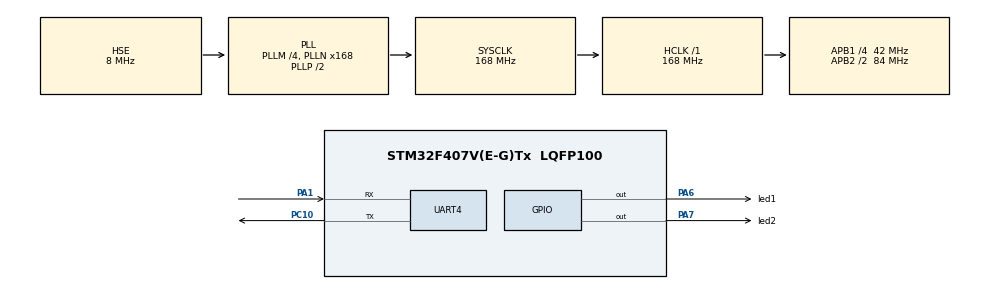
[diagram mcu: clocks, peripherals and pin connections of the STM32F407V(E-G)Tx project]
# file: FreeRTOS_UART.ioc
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FREERTOS.BinarySemaphores01=uartBinarySem,Dynamic,NULL;mainBinarySem,Dynamic,NULL
FREERTOS.Tasks01=defaultTask,0,128,StartDefaultTask,Default,NULL,Dynamic,NULL,NULL;uartProcess,0,128,StartUartProcess,Default,NULL,Dynamic,NULL,NULL
Mcu.Family=STM32F4
Mcu.Name=STM32F407V(E-G)Tx
Mcu.Package=LQFP100
NVIC.PriorityGroup=NVIC_PRIORITYGROUP_4
NVIC.TIM7_IRQn=true\:0\:0\:false\:false\:true\:false\:false\:true
NVIC.TimeBase=TIM7_IRQn
NVIC.TimeBaseIP=TIM7
NVIC.UART4_IRQn=true\:5\:0\:true\:false\:true\:true\:true\:true
PA1.Mode=Asynchronous
PA1.Signal=UART4_RX
PA13.Mode=Serial_Wire
PA13.Signal=SYS_JTMS-SWDIO
PA14.Mode=Serial_Wire
PA14.Signal=SYS_JTCK-SWCLK
PA6.GPIO_Label=led1
PA6.Signal=GPIO_Output
PA7.GPIO_Label=led2
PA7.GPIO_PuPd=GPIO_PULLDOWN
PA7.Signal=GPIO_Output
PC10.Mode=Asynchronous
PC10.Signal=UART4_TX
PH0-OSC_IN.Mode=HSE-External-Oscillator
PH0-OSC_IN.Signal=RCC_OSC_IN
PH1-OSC_OUT.Mode=HSE-External-Oscillator
PH1-OSC_OUT.Signal=RCC_OSC_OUT
ProjectManager.HeapSize=0x200
ProjectManager.StackSize=0x400
ProjectManager.TargetToolchain=STM32CubeIDE
RCC.48MHZClocksFreq_Value=84000000
RCC.AHBFreq_Value=168000000
RCC.APB1CLKDivider=RCC_HCLK_DIV4
RCC.APB1Freq_Value=42000000
RCC.APB1TimFreq_Value=84000000
RCC.APB2CLKDivider=RCC_HCLK_DIV2
RCC.APB2Freq_Value=84000000
RCC.APB2TimFreq_Value=168000000
RCC.CortexFreq_Value=168000000
RCC.HCLKFreq_Value=168000000
RCC.HSE_VALUE=8000000
RCC.HSI_VALUE=16000000
RCC.LSE_VALUE=32768
RCC.PLLM=4
RCC.PLLN=168
RCC.PLLSourceVirtual=RCC_PLLSOURCE_HSE
RCC.SYSCLKFreq_VALUE=168000000
RCC.SYSCLKSource=RCC_SYSCLKSOURCE_PLLCLK
RCC.VCOOutputFreq_Value=336000000
UART4.VirtualMode=Asynchronous
VP_FREERTOS_VS_CMSIS_V1.Mode=CMSIS_V1
VP_SYS_VS_tim7.Mode=TIM7
board=custom

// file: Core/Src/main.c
/* USER CODE BEGIN Header */
/**
  ******************************************************************************
  * @file           : main.c
  * @brief          : Main program body
  ******************************************************************************
  * @attention
  *
  * <h2><center>&copy; Copyright (c) 2020 STMicroelectronics.
  * All rights reserved.</center></h2>
  *
  * This software component is licensed by ST under BSD 3-Clause license,
  * the "License"; You may not use this file except in compliance with the
  * License. You may obtain a copy of the License at:
  *                        opensource.org/licenses/BSD-3-Clause
  *
  ******************************************************************************
  */
/* USER CODE END Header */

#include "main.h"
#include "cmsis_os.h"

/* USER CODE BEGIN Includes */
#include <stdio.h>
/* USER CODE END Includes */

UART_HandleTypeDef huart4;

osThreadId defaultTaskHandle;
osThreadId uartProcessHandle;
osSemaphoreId uartBinarySemHandle;
osSemaphoreId mainBinarySemHandle;
/* USER CODE BEGIN PV */
volatile char recievedData[50];
/* USER CODE END PV */

void SystemClock_Config(void);
static void MX_GPIO_Init(void);
static void MX_UART4_Init(void);
void StartDefaultTask(void const * argument);
void StartUartProcess(void const * argument);

/* USER CODE BEGIN 0 */
void HAL_UART_RxCpltCallback(UART_HandleTypeDef *huart)
{
	memset(recievedData, 0, sizeof(recievedData));
	if(huart->Instance == UART4){
		osSemaphoreRelease(uartBinarySemHandle);
	}
}
/* USER CODE END 0 */

int main(void)
{

  /* MCU Configuration--------------------------------------------------------*/

  /* Reset of all peripherals, Initializes the Flash interface and the Systick. */
  HAL_Init();

  /* Configure the system clock */
  SystemClock_Config();

  /* Initialize all configured peripherals */
  MX_GPIO_Init();
  MX_UART4_Init();

  /* Create the semaphores(s) */
  /* definition and creation of uartBinarySem */
  osSemaphoreDef(uartBinarySem);
  uartBinarySemHandle = osSemaphoreCreate(osSemaphore(uartBinarySem), 1);

  /* definition and creation of mainBinarySem */
  osSemaphoreDef(mainBinarySem);
  mainBinarySemHandle = osSemaphoreCreate(osSemaphore(mainBinarySem), 1);

  /* Create the thread(s) */
  /* definition and creation of defaultTask */
  osThreadDef(defaultTask, StartDefaultTask, osPriorityNormal, 0, 128);
  defaultTaskHandle = osThreadCreate(osThread(defaultTask), NULL);

  /* definition and creation of uartProcess */
  osThreadDef(uartProcess, StartUartProcess, osPriorityNormal, 0, 128);
  uartProcessHandle = osThreadCreate(osThread(uartProcess), NULL);

  /* USER CODE BEGIN RTOS_THREADS */
  /* add threads, ... */
  HAL_UART_Receive_IT(&huart4, (uint8_t*)recievedData, 1);
  /* USER CODE END RTOS_THREADS */

  /* Start scheduler */
  osKernelStart();

  /* We should never get here as control is now taken by the scheduler */
  /* Infinite loop */
  while (1)
  {

  }
}

void SystemClock_Config(void)
{
  RCC_OscInitTypeDef RCC_OscInitStruct = {0};
  RCC_ClkInitTypeDef RCC_ClkInitStruct = {0};

  /** Configure the main internal regulator output voltage
  */
  __HAL_RCC_PWR_CLK_ENABLE();
  __HAL_PWR_VOLTAGESCALING_CONFIG(PWR_REGULATOR_VOLTAGE_SCALE1);
  /** Initializes the CPU, AHB and APB busses clocks
  */
  RCC_OscInitStruct.OscillatorType = RCC_OSCILLATORTYPE_HSE;
  RCC_OscInitStruct.HSEState = RCC_HSE_ON;
  RCC_OscInitStruct.PLL.PLLState = RCC_PLL_ON;
  RCC_OscInitStruct.PLL.PLLSource = RCC_PLLSOURCE_HSE;
  RCC_OscInitStruct.PLL.PLLM = 4;
  RCC_OscInitStruct.PLL.PLLN = 168;
  RCC_OscInitStruct.PLL.PLLP = RCC_PLLP_DIV2;
  RCC_OscInitStruct.PLL.PLLQ = 4;
  if (HAL_RCC_OscConfig(&RCC_OscInitStruct) != HAL_OK)
  {
    Error_Handler();
  }
  /** Initializes the CPU, AHB and APB busses clocks
  */
  RCC_ClkInitStruct.ClockType = RCC_CLOCKTYPE_HCLK|RCC_CLOCKTYPE_SYSCLK
                              |RCC_CLOCKTYPE_PCLK1|RCC_CLOCKTYPE_PCLK2;
  RCC_ClkInitStruct.SYSCLKSource = RCC_SYSCLKSOURCE_PLLCLK;
  RCC_ClkInitStruct.AHBCLKDivider = RCC_SYSCLK_DIV1;
  RCC_ClkInitStruct.APB1CLKDivider = RCC_HCLK_DIV4;
  RCC_ClkInitStruct.APB2CLKDivider = RCC_HCLK_DIV2;

  if (HAL_RCC_ClockConfig(&RCC_ClkInitStruct, FLASH_LATENCY_5) != HAL_OK)
  {
    Error_Handler();
  }
}

static void MX_UART4_Init(void)
{

  huart4.Instance = UART4;
  huart4.Init.BaudRate = 115200;
  huart4.Init.WordLength = UART_WORDLENGTH_8B;
  huart4.Init.StopBits = UART_STOPBITS_1;
  huart4.Init.Parity = UART_PARITY_NONE;
  huart4.Init.Mode = UART_MODE_TX_RX;
  huart4.Init.HwFlowCtl = UART_HWCONTROL_NONE;
  huart4.Init.OverSampling = UART_OVERSAMPLING_16;
  if (HAL_UART_Init(&huart4) != HAL_OK)
  {
    Error_Handler();
  }

}

static void MX_GPIO_Init(void)
{
  GPIO_InitTypeDef GPIO_InitStruct = {0};

  /* GPIO Ports Clock Enable */
  __HAL_RCC_GPIOH_CLK_ENABLE();
  __HAL_RCC_GPIOA_CLK_ENABLE();
  __HAL_RCC_GPIOC_CLK_ENABLE();

  /*Configure GPIO pin Output Level */
  HAL_GPIO_WritePin(GPIOA, led1_Pin|led2_Pin, GPIO_PIN_RESET);

  /*Configure GPIO pin : led1_Pin */
  GPIO_InitStruct.Pin = led1_Pin;
  GPIO_InitStruct.Mode = GPIO_MODE_OUTPUT_PP;
  GPIO_InitStruct.Pull = GPIO_NOPULL;
  GPIO_InitStruct.Speed = GPIO_SPEED_FREQ_LOW;
  HAL_GPIO_Init(led1_GPIO_Port, &GPIO_InitStruct);

  /*Configure GPIO pin : led2_Pin */
  GPIO_InitStruct.Pin = led2_Pin;
  GPIO_InitStruct.Mode = GPIO_MODE_OUTPUT_PP;
  GPIO_InitStruct.Pull = GPIO_PULLDOWN;
  GPIO_InitStruct.Speed = GPIO_SPEED_FREQ_LOW;
  HAL_GPIO_Init(led2_GPIO_Port, &GPIO_InitStruct);

}

void StartDefaultTask(void const * argument)
{
  /* USER CODE BEGIN 5 */
  /* Infinite loop */
  for(;;)
  {
	  HAL_GPIO_TogglePin(led1_GPIO_Port, led1_Pin);
	  osDelay(100);
  }
  /* USER CODE END 5 */
}

void StartUartProcess(void const * argument)
{
  /* USER CODE BEGIN StartUartProcess */
  /* Infinite loop */
  for(;;)
  {
	  osSemaphoreWait(uartBinarySemHandle, osWaitForever);
	  HAL_UART_Receive(&huart4,(uint8_t*)recievedData,50,300);
	  HAL_UART_Transmit(&huart4, (uint8_t*)recievedData, sizeof(recievedData), 10);
	  HAL_UART_Receive_IT(&huart4, (uint8_t*)recievedData, 1);
	  osDelay(1);
  }
  /* USER CODE END StartUartProcess */
}

 /**
  * @brief  Period elapsed callback in non blocking mode
  * @note   This function is called  when TIM7 interrupt took place, inside
  * HAL_TIM_IRQHandler(). It makes a direct call to HAL_IncTick() to increment
  * a global variable "uwTick" used as application time base.
  * @param  htim : TIM handle
  * @retval None
  */
void HAL_TIM_PeriodElapsedCallback(TIM_HandleTypeDef *htim)
{
  if (htim->Instance == TIM7) {
    HAL_IncTick();
  }
}

void Error_Handler(void)
{
}

/************************ (C) COPYRIGHT STMicroelectronics *****END OF FILE****/
